# CY8C5267AXI_LP051 register map
File version: 0.1
CY8C52LP
Registers are 8-bit, read-write, no defined reset value unless marked. A register's access mark holds for its fields unless they carry their own. Offsets are from the block's base; lines under a group give offsets from that group; [hi:lo] are bit positions; {n}, {i} and the like mark numbered series; 'fields as' and 'values as' point back to an identical list; <NAME> marks a mode.

## Memory map
0x00000000 Control_Reg_2
0x00000000 UART_Data_Z2P
0x00000000 Status_Reg_2
0x00000000 UART_Data_P2Z
0x00000000 MEM_CTRL
0x00000000 Z80_IO_Address
0x00000000 UART_1 — UART
0x00000000 DMA_A8_15
0x00000000 BANK_REG
0x00000000 DMA_A0_7

## Control_Reg_2
Base 0x00000000
0x40006477 Control_Reg_2_CONTROL_REG

## UART_Data_Z2P
Base 0x00000000
0x40006463 UART_Data_Z2P_STATUS_REG
0x40006483 UART_Data_Z2P_MASK_REG
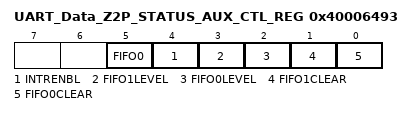
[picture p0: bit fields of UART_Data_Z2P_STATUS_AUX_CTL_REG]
0x40006493 UART_Data_Z2P_STATUS_AUX_CTL_REG
  [5] FIFO0 — FIFO0 clear
    1=ENABLED (Enable counter); 0=DISABLED (Disable counter)
  [4] INTRENBL — Enables or disables the Interrupt
    1=ENABLED (Interrupt enabled); 0=DISABLED (Interrupt disabled)
  [3] FIFO1LEVEL — FIFO level
    1=ENABLED (FIFO LVL: input mode: FIFO at least 1/2 empty; output mode: FIFO at least 1/2 full); 0=DISABLED (FIFO LVL: input mode: FIFO not full; output mode: FIFO not empty)
  [2] FIFO0LEVEL — FIFO level
    values as FIFO1LEVEL
  [1] FIFO1CLEAR — FIFO clear
    1=ENABLED (Clear FIFO state); 0=DISABLED (Normal FIFO operation)
  [0] FIFO0CLEAR — FIFO clear
    values as FIFO1CLEAR

## Status_Reg_2
Base 0x00000000
0x40006566 Status_Reg_2_STATUS_REG
0x40006586 Status_Reg_2_MASK_REG
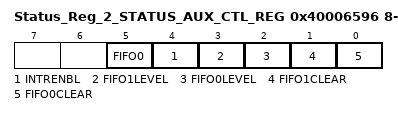
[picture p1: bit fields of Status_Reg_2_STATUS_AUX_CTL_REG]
0x40006596 Status_Reg_2_STATUS_AUX_CTL_REG
  fields as UART_Data_Z2P.UART_Data_Z2P_STATUS_AUX_CTL_REG

## UART_Data_P2Z
Base 0x00000000
0x40006475 UART_Data_P2Z_CONTROL_REG

## MEM_CTRL
Base 0x00000000
0x40006473 MEM_CTRL_CONTROL_REG

## Z80_IO_Address
Base 0x00000000
0x40006567 Z80_IO_Address_STATUS_REG
0x40006587 Z80_IO_Address_MASK_REG
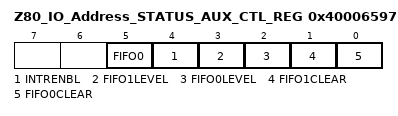
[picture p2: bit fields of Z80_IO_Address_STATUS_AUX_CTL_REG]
0x40006597 Z80_IO_Address_STATUS_AUX_CTL_REG
  fields as UART_Data_Z2P.UART_Data_Z2P_STATUS_AUX_CTL_REG

## UART_1 — UART
Base 0x00000000
0x40006425 RX_UART_1_RX_ADDRESS1 — RX Address1 Register
0x40006435 RX_UART_1_RX_ADDRESS2 — RX Address2 Register
0x40006445 RX_UART_1_RX_DATA — RX Data Register
0x40006448 TX_UART_1_TX_DATA — TX Data Register
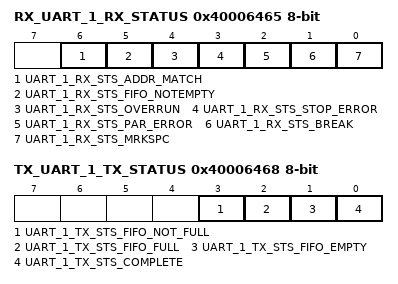
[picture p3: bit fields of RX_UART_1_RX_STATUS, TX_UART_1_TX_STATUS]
0x40006465 RX_UART_1_RX_STATUS — RX status register
  [6] UART_1_RX_STS_ADDR_MATCH ro, [5] UART_1_RX_STS_FIFO_NOTEMPTY ro, [4] UART_1_RX_STS_OVERRUN ro, [3] UART_1_RX_STS_STOP_ERROR ro, [2] UART_1_RX_STS_PAR_ERROR ro, [1] UART_1_RX_STS_BREAK ro, [0] UART_1_RX_STS_MRKSPC ro
0x40006468 TX_UART_1_TX_STATUS — TX status register
  [3] UART_1_TX_STS_FIFO_NOT_FULL ro, [2] UART_1_TX_STS_FIFO_FULL ro, [1] UART_1_TX_STS_FIFO_EMPTY ro, [0] UART_1_TX_STS_COMPLETE ro

## DMA_A8_15
Base 0x00000000
0x40006478 DMA_A8_15_CONTROL_REG

## BANK_REG
Base 0x00000000
0x40006474 BANK_REG_CONTROL_REG

## DMA_A0_7
Base 0x00000000
0x40006479 DMA_A0_7_CONTROL_REG
